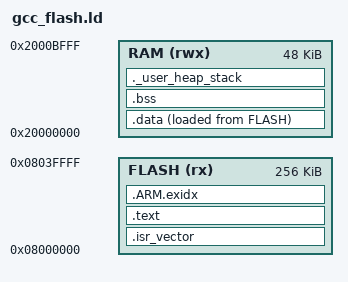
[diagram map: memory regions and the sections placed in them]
ENTRY(Reset_Handler)
MEMORY
{
  FLASH (rx) : ORIGIN = 0x08000000, LENGTH = 256K
  RAM (rwx) : ORIGIN = 0x20000000, LENGTH = 48K
}
SECTIONS {
  .isr_vector : { KEEP(*(.isr_vector)) } > FLASH
  .text : { *(.text*) *(.rodata*) } > FLASH
  .ARM.exidx : { *(.ARM.exidx*) } > FLASH
  .data : { _sidata = LOADADDR(.data); _sdata = .; *(.data*) _edata = .; } > RAM AT > FLASH
  .bss : { _sbss = .; *(.bss*) *(COMMON) _ebss = .; } > RAM
  ._user_heap_stack : { . = ALIGN(8); . = . + 0x400; } > RAM
  _estack = ORIGIN(RAM) + LENGTH(RAM);
}
